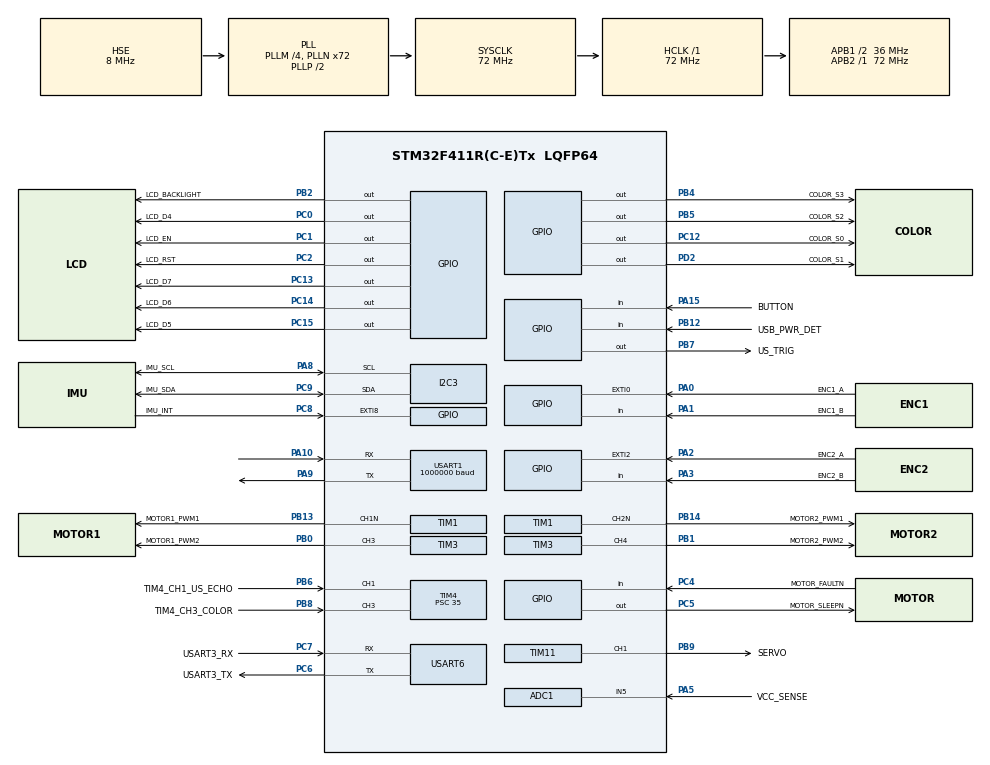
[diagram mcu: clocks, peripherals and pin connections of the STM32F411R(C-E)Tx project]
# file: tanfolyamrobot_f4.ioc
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ADC1.Channel-0\#ChannelRegularConversion=ADC_CHANNEL_5
ADC1.NbrOfConversionFlag=1
ADC1.Rank-0\#ChannelRegularConversion=1
ADC1.SamplingTime-0\#ChannelRegularConversion=ADC_SAMPLETIME_3CYCLES
ADC1.master=1
Dma.Request0=USART1_TX
Dma.Request1=USART6_TX
Dma.USART1_TX.0.Direction=DMA_MEMORY_TO_PERIPH
Dma.USART1_TX.0.FIFOMode=DMA_FIFOMODE_DISABLE
Dma.USART1_TX.0.Instance=DMA2_Stream7
Dma.USART1_TX.0.MemDataAlignment=DMA_MDATAALIGN_BYTE
Dma.USART1_TX.0.MemInc=DMA_MINC_ENABLE
Dma.USART1_TX.0.Mode=DMA_NORMAL
Dma.USART1_TX.0.PeriphDataAlignment=DMA_PDATAALIGN_BYTE
Dma.USART1_TX.0.PeriphInc=DMA_PINC_DISABLE
Dma.USART1_TX.0.Priority=DMA_PRIORITY_HIGH
Dma.USART6_TX.1.Direction=DMA_MEMORY_TO_PERIPH
Dma.USART6_TX.1.FIFOMode=DMA_FIFOMODE_DISABLE
Dma.USART6_TX.1.Instance=DMA2_Stream6
Dma.USART6_TX.1.MemDataAlignment=DMA_MDATAALIGN_BYTE
Dma.USART6_TX.1.MemInc=DMA_MINC_ENABLE
Dma.USART6_TX.1.Mode=DMA_NORMAL
Dma.USART6_TX.1.PeriphDataAlignment=DMA_PDATAALIGN_BYTE
Dma.USART6_TX.1.PeriphInc=DMA_PINC_DISABLE
Dma.USART6_TX.1.Priority=DMA_PRIORITY_HIGH
I2C3.I2C_Mode=I2C_Fast
Mcu.Family=STM32F4
Mcu.Name=STM32F411R(C-E)Tx
Mcu.Package=LQFP64
NVIC.ADC_IRQn=true\:15\:0\:true\:false\:true\:true\:true\:true
NVIC.DMA2_Stream6_IRQn=true\:0\:0\:false\:false\:true\:false\:true\:true
NVIC.DMA2_Stream7_IRQn=true\:0\:0\:false\:false\:true\:false\:true\:true
NVIC.EXTI0_IRQn=true\:2\:0\:true\:false\:true\:true\:true\:true
NVIC.EXTI2_IRQn=true\:2\:0\:true\:false\:true\:true\:true\:true
NVIC.I2C3_EV_IRQn=true\:0\:0\:false\:false\:true\:true\:true\:true
NVIC.PriorityGroup=NVIC_PRIORITYGROUP_4
NVIC.TIM1_UP_TIM10_IRQn=true\:2\:0\:true\:false\:true\:true\:true\:true
NVIC.TIM4_IRQn=true\:2\:0\:true\:false\:true\:true\:true\:true
NVIC.USART1_IRQn=true\:0\:0\:false\:false\:true\:true\:true\:true
NVIC.USART6_IRQn=true\:0\:0\:false\:false\:true\:true\:true\:true
PA0-WKUP.GPIO_Label=ENC1_A
PA0-WKUP.Signal=GPXTI0
PA1.GPIO_Label=ENC1_B
PA1.Signal=GPIO_Input
PA10.Mode=Asynchronous
PA10.Signal=USART1_RX
PA13.Mode=Serial_Wire
PA13.Signal=SYS_JTMS-SWDIO
PA14.Mode=Serial_Wire
PA14.Signal=SYS_JTCK-SWCLK
PA15.GPIO_Label=BUTTON
PA15.Signal=GPIO_Input
PA2.GPIO_Label=ENC2_A
PA2.Signal=GPXTI2
PA3.GPIO_Label=ENC2_B
PA3.Signal=GPIO_Input
PA5.GPIO_Label=VCC_SENSE
PA5.Signal=ADCx_IN5
PA8.GPIO_Label=IMU_SCL
PA8.Mode=I2C
PA8.Signal=I2C3_SCL
PA9.Mode=Asynchronous
PA9.Signal=USART1_TX
PB0.GPIO_Label=MOTOR1_PWM2
PB0.Signal=S_TIM3_CH3
PB1.GPIO_Label=MOTOR2_PWM2
PB1.Signal=S_TIM3_CH4
PB12.GPIO_Label=USB_PWR_DET
PB12.Signal=GPIO_Input
PB13.GPIO_Label=MOTOR1_PWM1
PB13.Mode=PWM Generation1 CH1N
PB13.Signal=TIM1_CH1N
PB14.GPIO_Label=MOTOR2_PWM1
PB14.Mode=PWM Generation2 CH2N
PB14.Signal=TIM1_CH2N
PB2.GPIO_Label=LCD_BACKLIGHT
PB2.Signal=GPIO_Output
PB4.GPIO_Label=COLOR_S3
PB4.Signal=GPIO_Output
PB5.GPIO_Label=COLOR_S2
PB5.Signal=GPIO_Output
PB6.GPIO_Label=TIM4_CH1_US_ECHO
PB6.Signal=S_TIM4_CH1
PB7.GPIO_Label=US_TRIG
PB7.Signal=GPIO_Output
PB8.GPIO_Label=TIM4_CH3_COLOR
PB8.Signal=S_TIM4_CH3
PB9.GPIO_Label=SERVO
PB9.Signal=S_TIM11_CH1
PC0.GPIO_Label=LCD_D4
PC0.Signal=GPIO_Output
PC1.GPIO_Label=LCD_EN
PC1.Signal=GPIO_Output
PC12.GPIO_Label=COLOR_S0
PC12.Signal=GPIO_Output
PC13-ANTI_TAMP.GPIO_Label=LCD_D7
PC13-ANTI_TAMP.Signal=GPIO_Output
PC14-OSC32_IN.GPIO_Label=LCD_D6
PC14-OSC32_IN.Signal=GPIO_Output
PC15-OSC32_OUT.GPIO_Label=LCD_D5
PC15-OSC32_OUT.Signal=GPIO_Output
PC2.GPIO_Label=LCD_RST
PC2.Signal=GPIO_Output
PC4.GPIO_Label=MOTOR_FAULTN
PC4.Signal=GPIO_Input
PC5.GPIO_Label=MOTOR_SLEEPN
PC5.Signal=GPIO_Output
PC6.GPIO_Label=USART3_TX
PC6.Mode=Asynchronous
PC6.Signal=USART6_TX
PC7.GPIO_Label=USART3_RX
PC7.Mode=Asynchronous
PC7.Signal=USART6_RX
PC8.GPIO_Label=IMU_INT
PC8.Signal=GPXTI8
PC9.GPIO_Label=IMU_SDA
PC9.Mode=I2C
PC9.Signal=I2C3_SDA
PD2.GPIO_Label=COLOR_S1
PD2.Signal=GPIO_Output
PH0\ -\ OSC_IN.Mode=HSE-External-Oscillator
PH0\ -\ OSC_IN.Signal=RCC_OSC_IN
PH1\ -\ OSC_OUT.Mode=HSE-External-Oscillator
PH1\ -\ OSC_OUT.Signal=RCC_OSC_OUT
ProjectManager.HeapSize=0x200
ProjectManager.StackSize=0x400
ProjectManager.TargetToolchain=STM32CubeIDE
RCC.48MHZClocksFreq_Value=36000000
RCC.AHBFreq_Value=72000000
RCC.APB1CLKDivider=RCC_HCLK_DIV2
RCC.APB1Freq_Value=36000000
RCC.APB1TimFreq_Value=72000000
RCC.APB2Freq_Value=72000000
RCC.APB2TimFreq_Value=72000000
RCC.CortexFreq_Value=72000000
RCC.HCLKFreq_Value=72000000
RCC.HSE_VALUE=8000000
RCC.HSI_VALUE=16000000
RCC.LSE_VALUE=32768
RCC.PLLM=4
RCC.PLLN=72
RCC.PLLSourceVirtual=RCC_PLLSOURCE_HSE
RCC.SYSCLKFreq_VALUE=72000000
RCC.SYSCLKSource=RCC_SYSCLKSOURCE_PLLCLK
RCC.VCOOutputFreq_Value=144000000
SH.ADCx_IN5.0=ADC1_IN5,IN5
SH.S_TIM11_CH1.0=TIM11_CH1,PWM Generation1 CH1
SH.S_TIM3_CH3.0=TIM3_CH3,PWM Generation3 CH3
SH.S_TIM3_CH4.0=TIM3_CH4,PWM Generation4 CH4
SH.S_TIM4_CH1.0=TIM4_CH1,Input_Capture1_from_TI1
SH.S_TIM4_CH3.0=TIM4_CH3,Input_Capture3_from_TI3
TIM1.Channel-PWM\ Generation1\ CH1N=TIM_CHANNEL_1
TIM1.Channel-PWM\ Generation2\ CH2N=TIM_CHANNEL_2
TIM1.Period=4500
TIM11.AutoReloadPreload=TIM_AUTORELOAD_PRELOAD_ENABLE
TIM11.Channel=TIM_CHANNEL_1
TIM11.OCPolarity_1=TIM_OCPOLARITY_LOW
TIM11.Period=20000
TIM11.Prescaler=71
TIM3.AutoReloadPreload=TIM_AUTORELOAD_PRELOAD_ENABLE
TIM3.Channel-PWM\ Generation3\ CH3=TIM_CHANNEL_3
TIM3.Channel-PWM\ Generation4\ CH4=TIM_CHANNEL_4
TIM3.Period=4500
TIM4.AutoReloadPreload=TIM_AUTORELOAD_PRELOAD_ENABLE
TIM4.Channel-Input_Capture1_from_TI1=TIM_CHANNEL_1
TIM4.Channel-Input_Capture2_from_TI1_63=TIM_CHANNEL_2
TIM4.Channel-Input_Capture3_from_TI3=TIM_CHANNEL_3
TIM4.Channel-Output\ Compare4\ No\ Output=TIM_CHANNEL_4
TIM4.ICFilter_CH1=15
TIM4.ICPolarity_CH2=TIM_INPUTCHANNELPOLARITY_FALLING
TIM4.Prescaler=35
USART1.BaudRate=1000000
USART1.VirtualMode=VM_ASYNC
USART6.VirtualMode=VM_ASYNC
VP_TIM11_VS_ClockSourceINT.Mode=Enable_Timer
VP_TIM1_VS_ClockSourceINT.Mode=Internal
VP_TIM3_VS_ClockSourceINT.Mode=Internal
VP_TIM4_VS_ClockSourceINT.Mode=Internal
VP_TIM4_VS_indirect_ch1.Mode=Input_Capture2_from_TI1_63
VP_TIM4_VS_no_output4.Mode=Output Compare4 No Output
board=custom

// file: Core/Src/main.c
/* USER CODE BEGIN Header */
/**
  ******************************************************************************
  * @file           : main.c
  * @brief          : Main program body
  ******************************************************************************
  * @attention
  *
  * Copyright (c) 2023 STMicroelectronics.
  * All rights reserved.
  *
  * This software is licensed under terms that can be found in the LICENSE file
  * in the root directory of this software component.
  * If no LICENSE file comes with this software, it is provided AS-IS.
  *
  ******************************************************************************
  */
/* USER CODE END Header */
#include "main.h"
#include "adc.h"
#include "dma.h"
#include "i2c.h"
#include "tim.h"
#include "usart.h"
#include "gpio.h"

/* USER CODE BEGIN Includes */
#include "main_interface.h"
/* USER CODE END Includes */

void SystemClock_Config(void);

int main(void)
{

  /* MCU Configuration--------------------------------------------------------*/

  /* Reset of all peripherals, Initializes the Flash interface and the Systick. */
  HAL_Init();

  /* Configure the system clock */
  SystemClock_Config();

  /* Initialize all configured peripherals */
  MX_GPIO_Init();
  MX_DMA_Init();
  MX_ADC1_Init();
  MX_TIM1_Init();
  MX_TIM3_Init();
  MX_TIM4_Init();
  MX_USART6_UART_Init();
  MX_TIM11_Init();
  MX_I2C3_Init();
  MX_USART1_UART_Init();
  /* USER CODE BEGIN 2 */

  main_initRobot();
  main_runRobot();

  /* USER CODE END 2 */

  /* Infinite loop */
  while (1)
  {

  }
}

void SystemClock_Config(void)
{
  RCC_OscInitTypeDef RCC_OscInitStruct = {0};
  RCC_ClkInitTypeDef RCC_ClkInitStruct = {0};

  /** Configure the main internal regulator output voltage
  */
  __HAL_RCC_PWR_CLK_ENABLE();
  __HAL_PWR_VOLTAGESCALING_CONFIG(PWR_REGULATOR_VOLTAGE_SCALE1);

  /** Initializes the RCC Oscillators according to the specified parameters
  * in the RCC_OscInitTypeDef structure.
  */
  RCC_OscInitStruct.OscillatorType = RCC_OSCILLATORTYPE_HSE;
  RCC_OscInitStruct.HSEState = RCC_HSE_ON;
  RCC_OscInitStruct.PLL.PLLState = RCC_PLL_ON;
  RCC_OscInitStruct.PLL.PLLSource = RCC_PLLSOURCE_HSE;
  RCC_OscInitStruct.PLL.PLLM = 4;
  RCC_OscInitStruct.PLL.PLLN = 72;
  RCC_OscInitStruct.PLL.PLLP = RCC_PLLP_DIV2;
  RCC_OscInitStruct.PLL.PLLQ = 4;
  if (HAL_RCC_OscConfig(&RCC_OscInitStruct) != HAL_OK)
  {
    Error_Handler();
  }

  /** Initializes the CPU, AHB and APB buses clocks
  */
  RCC_ClkInitStruct.ClockType = RCC_CLOCKTYPE_HCLK|RCC_CLOCKTYPE_SYSCLK
                              |RCC_CLOCKTYPE_PCLK1|RCC_CLOCKTYPE_PCLK2;
  RCC_ClkInitStruct.SYSCLKSource = RCC_SYSCLKSOURCE_PLLCLK;
  RCC_ClkInitStruct.AHBCLKDivider = RCC_SYSCLK_DIV1;
  RCC_ClkInitStruct.APB1CLKDivider = RCC_HCLK_DIV2;
  RCC_ClkInitStruct.APB2CLKDivider = RCC_HCLK_DIV1;

  if (HAL_RCC_ClockConfig(&RCC_ClkInitStruct, FLASH_LATENCY_2) != HAL_OK)
  {
    Error_Handler();
  }
}

void Error_Handler(void)
{
  __disable_irq();
  while (1)
  {
  }
}
